# INSTR_CM_CORE_AON register map
Vendor: Texas Instruments
Peripheral module from a debugger description file (folder TDA3x).
Registers are 32-bit, access per field, reset 0x0 unless marked. A register's access mark holds for its fields unless they carry their own. Offsets are as the file gives them; lines under a group give offsets from that group; [hi:lo] are bit positions; {n}, {i} and the like mark numbered series; 'fields as' and 'values as' point back to an identical list; <NAME> marks a mode.

## INSTR_CM_CORE_AON
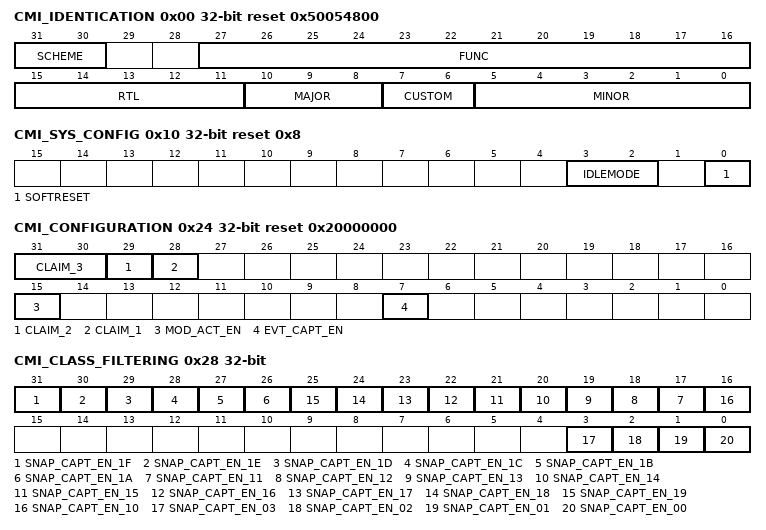
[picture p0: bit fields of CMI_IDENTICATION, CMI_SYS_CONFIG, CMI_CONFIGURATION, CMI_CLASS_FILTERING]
0x00 CMI_IDENTICATION ro reset 0x50054800 — CM profiling identification register
  [31:30] SCHEME
  [27:16] FUNC — Indicates a software compatible module family
  [15:11] RTL — RTL version
  [10:8] MAJOR — Major revision
  [7:6] CUSTOM — Indicates a special version for a particular device
  [5:0] MINOR — Minor revision
0x10 CMI_SYS_CONFIG reset 0x8 — CM profiling system configuartion register
  [3:2] IDLEMODE rw — Configuration of the local target state management mode
  [0] SOFTRESET rw — Software reset
0x14 CMI_STATUS ro reset 0x100 — CM profiling status register
  [8] FIFOEMPTY — PM Profiling buffer empty
0x24 CMI_CONFIGURATION reset 0x20000000 — CM profiling configuration register
  [31:30] CLAIM_3 rw — Ownership
  [29] CLAIM_2 rw — Debugger override qualifier
  [28] CLAIM_1 ro — Current owner
  [15] MOD_ACT_EN rw — When HIGH the CM Module Activity collection is enabled
  [7] EVT_CAPT_EN rw — When HIGH the CM events capture is enabled
0x28 CMI_CLASS_FILTERING — CM profiling class filtering register
  [31] SNAP_CAPT_EN_1F rw — Snapshot capture enable - Class-ID = 0x1F
  [30] SNAP_CAPT_EN_1E rw
  [29] SNAP_CAPT_EN_1D rw
  [28] SNAP_CAPT_EN_1C rw
  [27] SNAP_CAPT_EN_1B rw
  [26] SNAP_CAPT_EN_1A rw
  [n+6] SNAP_CAPT_EN_{n} rw (n=11..19)
  [16] SNAP_CAPT_EN_10 rw — Snapshot capture enable - Class-ID = 0x10
  [3] SNAP_CAPT_EN_03 rw — Snapshot capture enable - Class-ID = 0x03 [0x23]
  [2] SNAP_CAPT_EN_02 rw — Snapshot capture enable - Class-ID = 0x02 [0x22]
  [1] SNAP_CAPT_EN_01 rw — Snapshot capture enable - Class-ID = 0x01 [0x21]
  [0] SNAP_CAPT_EN_00 rw — Snapshot capture enable - Class-ID = 0x00 [0x20]
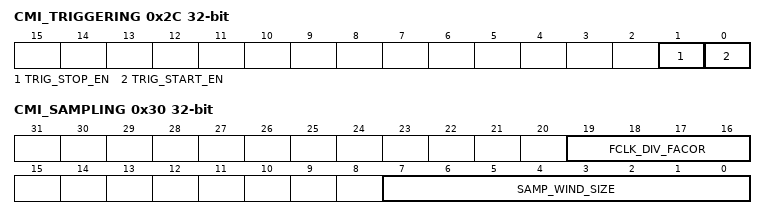
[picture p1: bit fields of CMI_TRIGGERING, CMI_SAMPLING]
0x2C CMI_TRIGGERING — CM profiling triggering control register
  [1] TRIG_STOP_EN rw — Enable stop capturing CM events from external trigger detection
  [0] TRIG_START_EN rw — Enable start capturing CM events from external trigger detection
0x30 CMI_SAMPLING — CM profiling sampling window register
  [19:16] FCLK_DIV_FACOR rw — FunClk divide factor ranging from 1 to 16
  [7:0] SAMP_WIND_SIZE rw — CM events sampling window size
